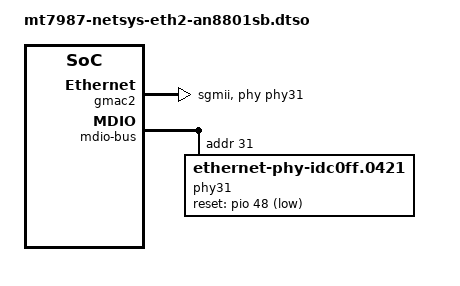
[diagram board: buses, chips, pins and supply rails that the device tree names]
// SPDX-License-Identifier: (GPL-2.0 OR MIT)

/dts-v1/;
/plugin/;

/ {
	fragment@0 {
		target = <&gmac2>;
		__overlay__ {
			phy-mode = "sgmii";
			phy-handle = <&phy31>;
			status = "okay";
		};
	};

	fragment@1 {
		target-path = "/soc_netsys/hnat@15000000";
		__overlay__ {
			mtketh-lan2 = "eth2";
			mtketh-max-gmac = <3>;
		};
	};

	fragment@2 {
		target-path = "/soc_netsys/ethernet@15100000/mdio-bus";
		__overlay__ {
			phy31: phy@31 {
				compatible = "ethernet-phy-idc0ff.0421";
				reg = <31>;
				reset-gpios = <&pio 48 1>;
				reset-assert-us = <10000>;
				reset-deassert-us = <10000>;
				phy-mode = "sgmii";
				airoha,sgmii-mode = <1>;
				eee-broken-100tx;
				eee-broken-1000t;
			};
		};
	};
};

